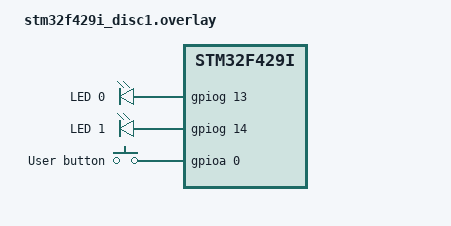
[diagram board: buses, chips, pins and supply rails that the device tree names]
#include <zephyr/dt-bindings/gpio/gpio.h>

/ {
	aliases {
		led0 = &led0;
		led1 = &led1;
		sw0 = &button0;
	};

	leds {
		compatible = "gpio-leds";
		led0: led_0 {
			gpios = <&gpiog 13 GPIO_ACTIVE_HIGH>;
			label = "LED 0";
		};
		led1: led_1 {
			gpios = <&gpiog 14 GPIO_ACTIVE_HIGH>;
			label = "LED 1";
		};
	};

	buttons {
		compatible = "gpio-keys";
		button0: button_0 {
			gpios = <&gpioa 0 (GPIO_PULL_DOWN | GPIO_ACTIVE_HIGH)>;
			label = "User button";
			zephyr,code = <INPUT_KEY_1>;
		};
	};
};

